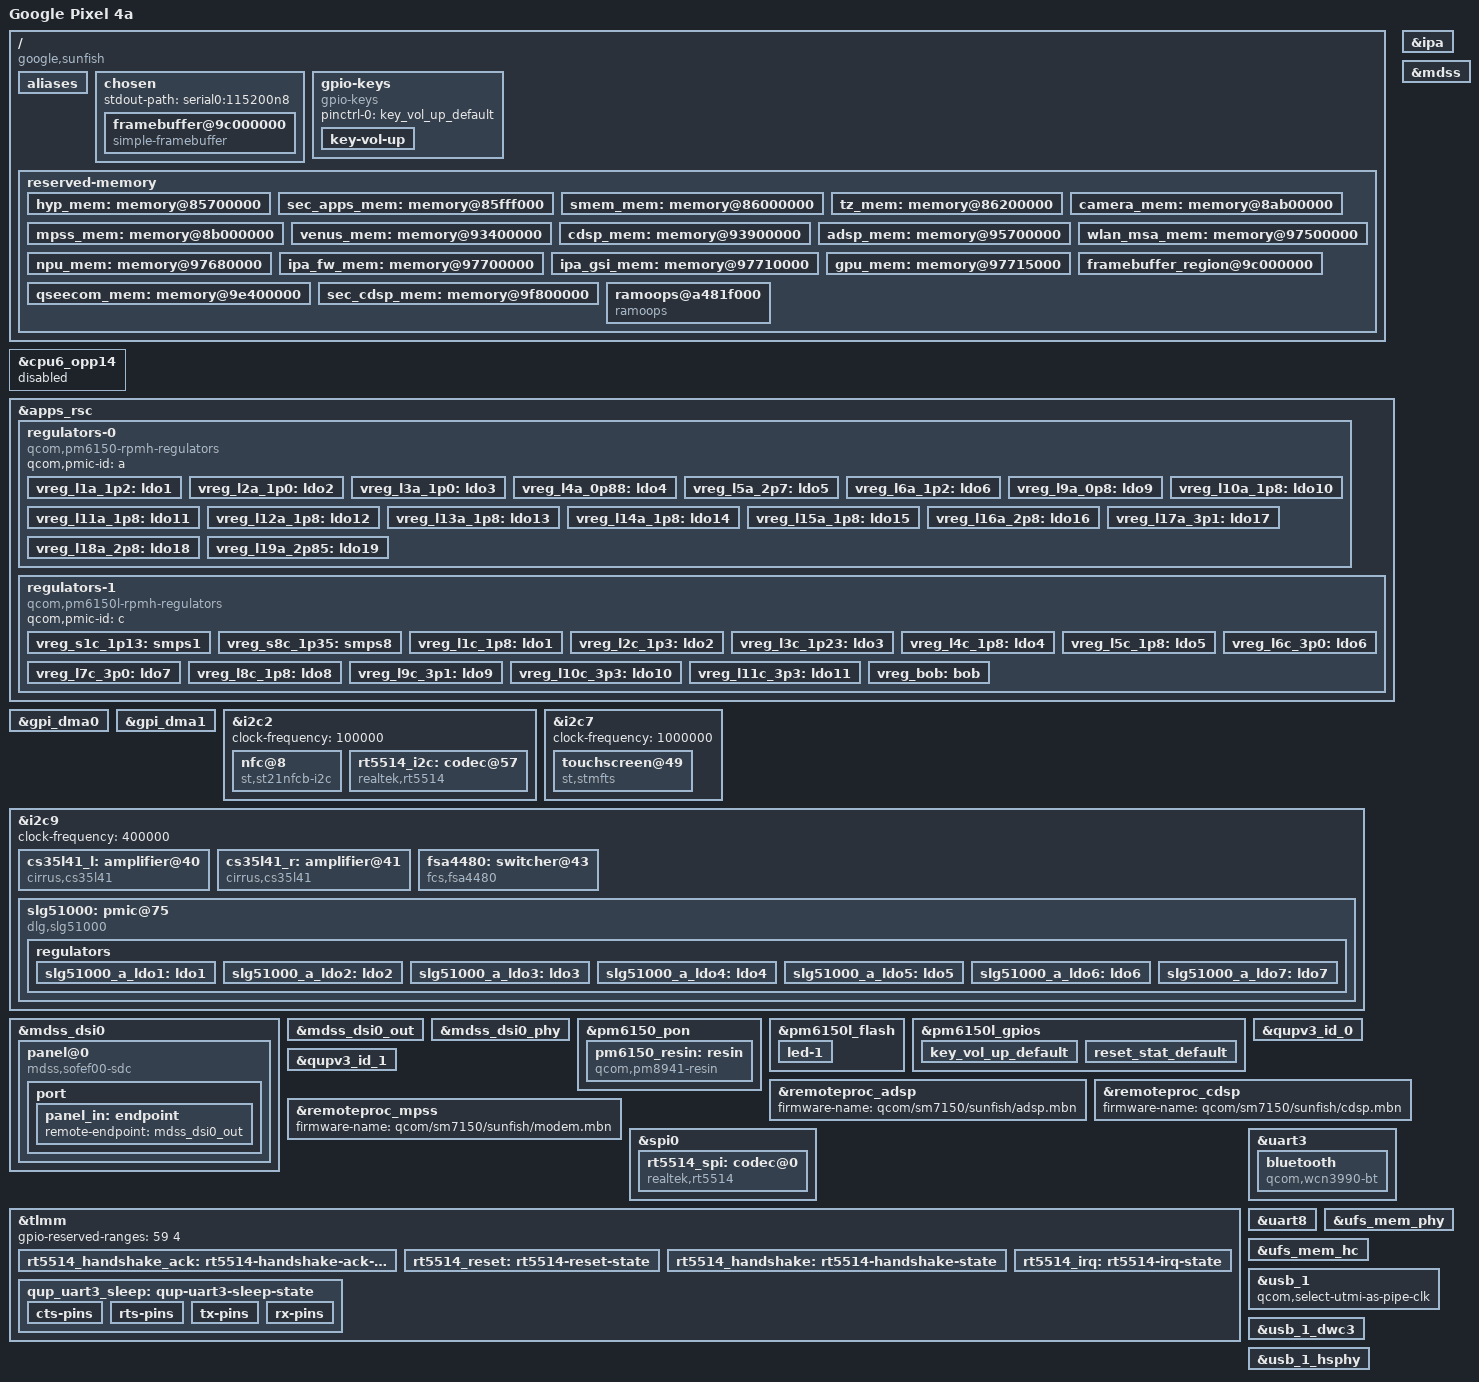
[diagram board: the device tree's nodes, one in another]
// SPDX-License-Identifier: BSD-3-Clause
/*
 * SM7150-AB Google Pixel 4a specific device tree
 *
 * Copyright (c) 2022, Connor Mitchell <c.dog29@hotmail.com>
 * Copyright (c) 2022, Danila Tikhonov <JIaxyga@protonmail.com>
 */

/dts-v1/;

#include <dt-bindings/arm/qcom,ids.h>
#include <dt-bindings/gpio/gpio.h>
#include <dt-bindings/leds/common.h>
#include <dt-bindings/regulator/qcom,rpmh-regulator.h>
#include <dt-bindings/pinctrl/qcom,pmic-gpio.h>

#include "sm7150.dtsi"
#include "pm6150.dtsi"
#include "pm6150l.dtsi"

/*
 * Delete following upstream (sm7150.dtsi) reserved
 * memory mappings which are different in this device.
 */
/delete-node/ &mpss_mem;
/delete-node/ &venus_mem;
/delete-node/ &cdsp_mem;
/delete-node/ &adsp_mem;
/delete-node/ &wlan_msa_mem;
/delete-node/ &npu_mem;
/delete-node/ &ipa_fw_mem;
/delete-node/ &ipa_gsi_mem;
/delete-node/ &gpu_mem;
/delete-node/ &hyp_mem;
/delete-node/ &sec_apps_mem;
/delete-node/ &smem_mem;
/delete-node/ &tz_mem;
/delete-node/ &camera_mem;
/delete-node/ &qseecom_mem;
/delete-node/ &sec_cdsp_mem;

/*
 * Sunfish uses the SM7150-AB SoC.
 * Limit CPU clock to 2.2 GHz
 */

 &cpu6_opp14 {
	status = "disabled";
};

/ {
	model = "Google Pixel 4a";
	compatible = "google,sunfish", "qcom,sm7150";
	chassis-type = "handset";

	qcom,msm-id = <QCOM_ID_SM7150 0>;
	qcom,board-id = <927749 0>;

	aliases {
		bluetooth0 = &bluetooth;
		hsuart0 = &uart3;
		serial0 = &uart8;
		wifi0 = &wifi;
	};

	chosen {
		stdout-path = "serial0:115200n8";
	};

	chosen {
		#address-cells = <2>;
		#size-cells = <2>;
		ranges;

		framebuffer@9c000000 {
			compatible = "simple-framebuffer";
			reg = <0x0 0x9c000000 0x0 (1080 * 2340 * 4)>;
			width = <1080>;
			height = <2340>;
			stride = <(1080 * 4)>;
			format = "a8r8g8b8";
			/*
			 * That's (going to be) a lot of clocks, but it's necessary due
			 * to unused clk cleanup & no panel driver yet (& no dispcc either)..
			 */
			clocks = <&gcc GCC_DISP_SF_AXI_CLK>;
		};
	};

	gpio-keys {
		compatible = "gpio-keys";
		pinctrl-names = "default";
		pinctrl-0 = <&key_vol_up_default>;

		key-vol-up {
			label = "Volume Up";
			linux,code = <KEY_VOLUMEUP>;
			gpios = <&pm6150l_gpios 2 GPIO_ACTIVE_LOW>;
			debounce-interval = <15>;
		};
	};

	reserved-memory { //Sort in order by unit address instead of the name
		hyp_mem: memory@85700000 {
			reg = <0x00 0x85700000 0x00 0x600000>;
			no-map;
		};

		sec_apps_mem: memory@85fff000 {
			reg = <0x00 0x85fff000 0x00 0x1000>;
			no-map;
		};

		smem_mem: memory@86000000 {
			reg = <0x00 0x86000000 0x00 0x200000>;
			no-map;
		};

		tz_mem: memory@86200000 {
			reg = <0x00 0x86200000 0x00 0x2d00000>;
			no-map;
		};

		camera_mem: memory@8ab00000 {
			reg = <0x00 0x8ab00000 0x00 0x500000>;
			no-map;
		};

		mpss_mem: memory@8b000000 {
			reg = <0x0 0x8b000000 0x0 0x9800000>;
			no-map;
		};

		venus_mem: memory@93400000 {
			reg = <0x00 0x94800000 0x00 0x500000>;
			no-map;
		};

		cdsp_mem: memory@93900000 {
			reg = <0x00 0x94d00000 0x00 0x1e00000>;
			no-map;
		};

		adsp_mem: memory@95700000 {
			reg = <0x00 0x96b00000 0x00 0x2200000>;
			no-map;
		};

		wlan_msa_mem: memory@97500000 {
			reg = <0x00 0x98d00000 0x00 0x200000>;
			no-map;
		};

		npu_mem: memory@97680000 {
			reg = <0x00 0x98f00000 0x00 0x80000>;
			no-map;
		};

		ipa_fw_mem: memory@97700000 {
			reg = <0x0 0x98f80000 0x0 0x10000>;
			no-map;
		};

		ipa_gsi_mem: memory@97710000 {
			reg = <0x0 0x98f90000 0x0 0x5000>;
			no-map;
		};

		gpu_mem: memory@97715000 {
			reg = <0x00 0x98f95000 0x00 0x2000>;
			no-map;
		};

		framebuffer_region@9c000000 {
			reg = <0x0 0x9c000000 0x0 (1080 * 2340 * 4)>;
			no-map;
		};

		qseecom_mem: memory@9e400000 {
			reg = <0x00 0x9e400000 0x00 0x1400000>;
			no-map;
		};

		sec_cdsp_mem: memory@9f800000 {
			reg = <0x00 0x9f800000 0x00 0x1e00000>;
			no-map;
		};

		ramoops@a481f000 {
			compatible = "ramoops";
			reg = <0x00 0xa481f000 0x00 0x400000>;

			record-size = <0x40000>;
			pmsg-size = <0x200000>;
			console-size = <0x100000>;
		};
	};
};

&apps_rsc {
	regulators-0 {
		compatible = "qcom,pm6150-rpmh-regulators";
		qcom,pmic-id = "a";

		vreg_l1a_1p2: ldo1 {
			regulator-min-microvolt = <0x10b940>;
			regulator-max-microvolt = <0x13e5c0>;
			regulator-initial-mode = <RPMH_REGULATOR_MODE_HPM>;
		};

		vreg_l2a_1p0: ldo2 {
			regulator-min-microvolt = <0xe6780>;
			regulator-max-microvolt = <0x101d00>;
			regulator-initial-mode = <RPMH_REGULATOR_MODE_HPM>;
		};

		vreg_l3a_1p0: ldo3 {
			regulator-min-microvolt = <0xec540>;
			regulator-max-microvolt = <0x103c40>;
			regulator-initial-mode = <RPMH_REGULATOR_MODE_HPM>;
		};

		vreg_l4a_0p88: ldo4 {
			regulator-min-microvolt = <0xc92c0>;
			regulator-max-microvolt = <0xe09c0>;
			regulator-initial-mode = <RPMH_REGULATOR_MODE_HPM>;
		};

		vreg_l5a_2p7: ldo5 {
			regulator-min-microvolt = <0x27ac40>;
			regulator-max-microvolt = <0x2ab980>;
			regulator-initial-mode = <RPMH_REGULATOR_MODE_HPM>;
		};

		vreg_l6a_1p2: ldo6 {
			regulator-min-microvolt = <0x10b940>;
			regulator-max-microvolt = <0x13e5c0>;
			regulator-initial-mode = <RPMH_REGULATOR_MODE_HPM>;
		};

		vreg_l9a_0p8: ldo9 {
			regulator-min-microvolt = <0x98580>;
			regulator-max-microvolt = <0xb98c0>;
			regulator-initial-mode = <RPMH_REGULATOR_MODE_HPM>;
		};

		vreg_l10a_1p8: ldo10 {
			regulator-min-microvolt = <0x1a3ec0>;
			regulator-max-microvolt = <0x1bf440>;
			regulator-initial-mode = <RPMH_REGULATOR_MODE_HPM>;
		};

		vreg_l11a_1p8: ldo11 {
			regulator-min-microvolt = <0x19e100>;
			regulator-max-microvolt = <0x1e4600>;
			regulator-initial-mode = <RPMH_REGULATOR_MODE_HPM>;
		};

		vreg_l12a_1p8: ldo12 {
			regulator-min-microvolt = <0x19e100>;
			regulator-max-microvolt = <0x1dc900>;
			regulator-initial-mode = <RPMH_REGULATOR_MODE_HPM>;
		};

		vreg_l13a_1p8: ldo13 {
			regulator-min-microvolt = <0x19e100>;
			regulator-max-microvolt = <0x1d0d80>;
			regulator-initial-mode = <RPMH_REGULATOR_MODE_HPM>;
		};

		vreg_l14a_1p8: ldo14 {
			regulator-min-microvolt = <0x1a3ec0>;
			regulator-max-microvolt = <0x1c5200>;
			regulator-initial-mode = <RPMH_REGULATOR_MODE_HPM>;
		};

		vreg_l15a_1p8: ldo15 {
			regulator-min-microvolt = <0x19e100>;
			regulator-max-microvolt = <0x1d0d80>;
			regulator-initial-mode = <RPMH_REGULATOR_MODE_HPM>;
		};

		vreg_l16a_2p8: ldo16 {
			regulator-min-microvolt = <0x24fcc0>;
			regulator-max-microvolt = "\0-i";
			regulator-initial-mode = <RPMH_REGULATOR_MODE_HPM>;
		};

		vreg_l17a_3p1: ldo17 {
			regulator-min-microvolt = <0x2dc6c0>;
			regulator-max-microvolt = "\01Q";
			regulator-initial-mode = <RPMH_REGULATOR_MODE_HPM>;
		};

		vreg_l18a_2p8: ldo18 {
			regulator-min-microvolt = <0x2dc6c0>;
			regulator-max-microvolt = <0x2dc6c0>;
			regulator-initial-mode = <RPMH_REGULATOR_MODE_HPM>;
		};

		vreg_l19a_2p85: ldo19 {
			regulator-min-microvolt = <0x2cec00>;
			regulator-max-microvolt = <0x326a40>;
			regulator-initial-mode = <RPMH_REGULATOR_MODE_HPM>;
		};
	};

	regulators-1 {
		compatible = "qcom,pm6150l-rpmh-regulators";
		qcom,pmic-id = "c";

		vreg_s1c_1p13: smps1 {
			regulator-min-microvolt = <0xf4240>;
			regulator-max-microvolt = <0x124f80>;
		};

		vreg_s8c_1p35: smps8 {
			regulator-min-microvolt = <0x124f80>;
			regulator-max-microvolt = <0x1a65d0>;
		};

		vreg_l1c_1p8: ldo1 {
			regulator-min-microvolt = <0x18a880>;
			regulator-max-microvolt = <0x1e4600>;
			regulator-initial-mode = <RPMH_REGULATOR_MODE_HPM>;
		};

		vreg_l2c_1p3: ldo2 {
			regulator-min-microvolt = <0x124f80>;
			regulator-max-microvolt = <0x14a140>;
			regulator-initial-mode = <RPMH_REGULATOR_MODE_HPM>;
		};

		vreg_l3c_1p23: ldo3 {
			regulator-min-microvolt = <0x1174c0>;
			regulator-max-microvolt = <0x132a40>;
			regulator-initial-mode = <RPMH_REGULATOR_MODE_HPM>;
		};

		vreg_l4c_1p8: ldo4 {
			regulator-min-microvolt = <0x192580>;
			regulator-max-microvolt = <0x2d0370>;
			regulator-initial-mode = <RPMH_REGULATOR_MODE_HPM>;
		};

		vreg_l5c_1p8: ldo5 {
			regulator-min-microvolt = <0x192580>;
			regulator-max-microvolt = <0x2d0370>;
			regulator-initial-mode = <RPMH_REGULATOR_MODE_HPM>;
		};

		vreg_l6c_3p0: ldo6 {
			regulator-min-microvolt = <0x2d2a80>;
			regulator-max-microvolt = <0x326a40>;
			regulator-initial-mode = <RPMH_REGULATOR_MODE_HPM>;
			regulator-allow-set-load;
			regulator-allowed-modes = <RPMH_REGULATOR_MODE_LPM
						   RPMH_REGULATOR_MODE_HPM>;
		};

		vreg_l7c_3p0: ldo7 {
			regulator-min-microvolt = <0x2dc6c0>;
			regulator-max-microvolt = <0x328980>;
			regulator-initial-mode = <RPMH_REGULATOR_MODE_HPM>;
		};

		vreg_l8c_1p8: ldo8 {
			regulator-min-microvolt = <0x1b7740>;
			regulator-max-microvolt = <0x1cfde0>;
			regulator-initial-mode = <RPMH_REGULATOR_MODE_HPM>;
		};

		/*
		 * Downstream specifies a range of 2950-3312mV.
		 * Tighten the range to 2950-3100mV.
		 */
		vreg_l9c_3p1: ldo9 {
			regulator-min-microvolt = <0x2d0370>;
			regulator-max-microvolt = <0x328980>;
			regulator-initial-mode = <RPMH_REGULATOR_MODE_HPM>;
			regulator-allow-set-load;
			regulator-allowed-modes = <RPMH_REGULATOR_MODE_LPM
						   RPMH_REGULATOR_MODE_HPM>;
		};

		vreg_l10c_3p3: ldo10 {
			regulator-min-microvolt = <0x30d400>;
			regulator-max-microvolt = <0x328980>;
			regulator-initial-mode = <RPMH_REGULATOR_MODE_HPM>;
		};

		vreg_l11c_3p3: ldo11 {
			regulator-min-microvolt = <0x2d0370>;
			regulator-max-microvolt = <0x33e140>;
			regulator-initial-mode = <RPMH_REGULATOR_MODE_HPM>;
		};

		vreg_bob: bob {
			regulator-min-microvolt = "\02K";
			regulator-max-microvolt = <0x3c6cc0>;
			regulator-initial-mode = <RPMH_REGULATOR_MODE_AUTO>;
			regulator-allow-bypass;
		};
	};
};

&gpi_dma0 {
	status = "okay";
};

&gpi_dma1 {
	status = "okay";
};

&i2c2 {
	clock-frequency = <100000>;
	status = "okay";
	nfc@8 {
		compatible = "st,st21nfcb-i2c";
		reg = <0x08>;

		interrupt-parent = <&tlmm>;
		interrupts = <37 IRQ_TYPE_NONE>;
		irq-gpio = <&tlmm 37 GPIO_ACTIVE_HIGH>;

		clkreq-gpios = <&tlmm 31 GPIO_ACTIVE_HIGH>;
		reset-gpios = <&tlmm 67 GPIO_ACTIVE_HIGH>;
		pidle-gpios = <&tlmm 94 GPIO_ACTIVE_HIGH>;

		ese-present;
		uicc-present;
	};

	/* nqx,nq-nci (nfc) @ 28 */

	rt5514_i2c: codec@57 {
		compatible = "realtek,rt5514";
		reg = <0x57>;
		reset-gpio = <&tlmm 33 GPIO_ACTIVE_HIGH>;
		pinctrl-names = "default";
		pinctrl-0 = <&rt5514_reset>;
	};
};

&i2c7 {
	clock-frequency = <1000000>;
	status = "okay";
	touchscreen@49 {
		compatible = "st,stmfts";
		reg = <0x49>;
		interrupt-parent = <&tlmm>;
		interrupts = <1 IRQ_TYPE_LEVEL_LOW>;
		touchscreen-size-x = <1079>;
		touchscreen-size-y = <2339>;
		avdd-supply = <&vreg_l13a_1p8>;
		vdd-supply = <&vreg_l14a_1p8>;
	};
};

&i2c9 {
	clock-frequency = <400000>;
	status= "okay";
	/* microchip,pac193x (dc power monitor) @ 10 */

	cs35l41_l: amplifier@40 {
		compatible = "cirrus,cs35l41";
		reg = <0x40>;
		interrupt-parent = <&tlmm>;
		interrupts = <64 IRQ_TYPE_LEVEL_HIGH>;
		reset-gpios = <&tlmm 8 GPIO_ACTIVE_HIGH>;
		cirrus,boost-peak-milliamp = <3700>;
		cirrus,boost-ind-nanohenry = <1000>;
		cirrus,boost-cap-microfarad = <15>;
		cirrus,asp-sdout-hiz = <3>;
		cirrus,gpio2-src-select = <5>;
		cirrus,gpio2-output-enable;
		#sound-dai-cells = <1>;
	};

	cs35l41_r: amplifier@41 {
		compatible = "cirrus,cs35l41";
		reg = <0x41>;
		interrupt-parent = <&tlmm>;
		interrupts = <65 IRQ_TYPE_LEVEL_HIGH>;
		reset-gpios = <&tlmm 11 GPIO_ACTIVE_HIGH>;
		cirrus,boost-peak-milliamp = <3700>;
		cirrus,boost-ind-nanohenry = <1000>;
		cirrus,boost-cap-microfarad = <15>;
		cirrus,asp-sdout-hiz = <3>;
		cirrus,gpio2-src-select = <5>;
		cirrus,gpio2-output-enable;
		#sound-dai-cells = <1>;
	};

	fsa4480: switcher@43 {
		compatible = "fcs,fsa4480";
		reg = <0x43>;

		interrupts-extended = <&tlmm 42 IRQ_TYPE_LEVEL_LOW>;

		vcc-supply = <&vreg_bob>;

		mode-switch;
		orientation-switch;
	};

	/* st,m24c08 (e2prom) @ 50 */
	/* ti,drv2624 (haptic) @ 5a */

	slg51000: pmic@75 {
		compatible = "dlg,slg51000";
		reg = <0x75>;
		dlg,cs-gpios = <&tlmm 4 GPIO_ACTIVE_HIGH>,
			       <&tlmm 6 GPIO_ACTIVE_HIGH>;
		dlg,enable-gpios = <&tlmm 1 GPIO_ACTIVE_HIGH>,
				   <&tlmm 5 GPIO_ACTIVE_HIGH>;

		regulators {
			slg51000_a_ldo1: ldo1 {
				regulator-name = "slg51000_a_ldo1";
				regulator-min-microvolt = <0x225510>;
				regulator-max-microvolt = <0x325aa0>;
			};

			slg51000_a_ldo2: ldo2 {
				regulator-name = "slg51000_a_ldo2";
				regulator-min-microvolt = <0x225510>;
				regulator-max-microvolt = <0x325aa0>;
			};

			slg51000_a_ldo3: ldo3 {
				regulator-name = "slg51000_a_ldo3";
				regulator-min-microvolt = <0x124f80>;
				regulator-max-microvolt = <0x393870>;
			};

			slg51000_a_ldo4: ldo4 {
				regulator-name = "slg51000_a_ldo4";
				regulator-min-microvolt = <0x124f80>;
				regulator-max-microvolt = <0x393870>;
			};

			slg51000_a_ldo5: ldo5 {
				regulator-name = "slg51000_a_ldo5";
				regulator-min-microvolt = <0x7a120>;
				regulator-max-microvolt = <0x124f80>;
			};

			slg51000_a_ldo6: ldo6 {
				regulator-name = "slg51000_a_ldo6";
				regulator-min-microvolt = <0x7a120>;
				regulator-max-microvolt = <0x124f80>;
			};

			slg51000_a_ldo7: ldo7 {
				regulator-name = "slg51000_a_ldo7";
				regulator-min-microvolt = <0x124f80>;
				regulator-max-microvolt = <0x393870>;
			};
		};
	};
};

&ipa {
	memory-region = <&ipa_fw_mem>;
	firmware-name = "qcom/sm7150/sunfish/ipa_fws.mbn";
	status = "okay";
};

&mdss {
	status = "okay";
};

&mdss_dsi0 {
	panel@0 {
		compatible = "mdss,sofef00-sdc";
		reg = <0>;

		reset-gpios = <&pm6150l_gpios 9 GPIO_ACTIVE_LOW>;

		port {
			panel_in: endpoint {
				remote-endpoint = <&mdss_dsi0_out>;
			};
		};
	};
};

&mdss_dsi0_out {
	data-lanes = <0 1 2 3>;
	remote-endpoint = <&panel_in>;
	status = "okay";
};
	
&mdss_dsi0_phy {
	status = "okay";
};

&pm6150_pon {
	pm6150_resin: resin {
		compatible = "qcom,pm8941-resin";
		interrupts = <0x0 0x8 1 IRQ_TYPE_EDGE_BOTH>;
		debounce = <15625>;
		bias-pull-up;
		linux,code = <KEY_VOLUMEDOWN>;
	};
};

&pm6150l_flash {
	status = "okay";

	led-1 {
		function = LED_FUNCTION_FLASH;
		color = <LED_COLOR_ID_WHITE>;
		led-sources = <1>;
		led-max-microamp = <150000>;
		flash-max-microamp = <1000000>;
		flash-max-timeout-us = <1280000>;
	};
};

&pm6150l_gpios {
	key_vol_up_default: key_vol_up_default {
		pins = "gpio2";
		function = "normal";
		input-enable;
		bias-pull-up;
		power-source = <0>;
	};

	reset_stat_default: reset_stat_default {
		pins = "gpio8";
		function = "normal";
		power-source = <1>;
		output-low;
		input-disable;
	};
};

&qupv3_id_0 {
	status = "okay";
};

&qupv3_id_1 {
	status = "okay";
};

&remoteproc_adsp {
	firmware-name = "qcom/sm7150/sunfish/adsp.mbn";
	status = "okay";
};

&remoteproc_cdsp {
	firmware-name = "qcom/sm7150/sunfish/cdsp.mbn";
	status = "okay";
};

&remoteproc_mpss {
	firmware-name = "qcom/sm7150/sunfish/modem.mbn";
	status = "okay";
};

&spi0 {
	status = "okay";

	rt5514_spi: codec@0 {
		compatible = "realtek,rt5514";
		reg = <0>;

		spi-max-frequency = <10000000>;

		interrupt-parent = <&tlmm>;
		interrupts = <58 IRQ_TYPE_NONE>,
			     <30 IRQ_TYPE_NONE>;
		interrupt-names = "irq", "handshake-ack";
		irq-gpio = <&tlmm 58 GPIO_ACTIVE_HIGH>;

		handshake-gpio = <&tlmm 57 0>;
		handshake-ack-gpio = <&tlmm 30 0>;
		pinctrl-names = "default";
		pinctrl-0 = <&rt5514_irq>,
			    <&rt5514_handshake>,
			    <&rt5514_handshake_ack>;
	};
};

&spi0 {
	status = "okay";

	/* google,citadel @ 0 */
	/* st,st54j_se @ 1 */
};

&tlmm {
	gpio-reserved-ranges = <59 4>;

	rt5514_handshake_ack: rt5514-handshake-ack-state {
		pins = "gpio30";
		function = "gpio";
		drive-strength = <2>;
		bias-pull-down;
		input-enable;
	};

	rt5514_reset: rt5514-reset-state {
		pins = "gpio33";
		function = "gpio";
		drive-strength = <2>;
		output-high;
	};

	rt5514_handshake: rt5514-handshake-state {
		pins = "gpio57";
		function = "gpio";
		drive-strength = <2>;
		output-low;
	};

	rt5514_irq: rt5514-irq-state {
		pins = "gpio58";
		function = "gpio";
		drive-strength = <2>;
		bias-pull-down;
		input-enable;
	};

	qup_uart3_sleep: qup-uart3-sleep-state {
		cts-pins {
			pins = "gpio38";
			function = "gpio";
			bias-pull-down;
		};

		rts-pins {
			pins = "gpio39";
			function = "gpio";
			bias-pull-down;
		};

		tx-pins {
			pins = "gpio40";
			function = "gpio";
			bias-pull-up;
		};

		rx-pins {
			pins = "gpio41";
			function = "gpio";
			bias-pull-up;
		};
	};
};

&uart3 {
	status = "okay";

	/delete-property/interrupts;
	interrupts-extended = <&intc GIC_SPI 604 IRQ_TYPE_LEVEL_HIGH>,
			      <&tlmm 41 IRQ_TYPE_EDGE_FALLING>;

	pinctrl-names = "default", "sleep";
	pinctrl-1 = <&qup_uart3_sleep>;

	bluetooth: bluetooth {
		compatible = "qcom,wcn3990-bt";

		vddio-supply = <&vreg_l10a_1p8>;
		vddxo-supply = <&vreg_l1c_1p8>;
		vddrf-supply = <&vreg_l2c_1p3>;
		vddch0-supply = <&vreg_l10c_3p3>;
		max-speed = <3200000>;
	};
};

&uart8 {
	status = "okay";
};

&ufs_mem_phy {
	status = "okay";

	vdda-phy-supply = <&vreg_l4a_0p88>;
	vdda-pll-supply = <&vreg_l3c_1p23>;
};

&ufs_mem_hc {
	status = "okay";

	vcc-supply = <&vreg_l19a_2p85>;
	vcc-max-microamp = <600000>;
	vccq2-supply = <&vreg_l12a_1p8>;
	vccq2-max-microamp = <600000>;
};

&usb_1 {
	status = "okay";

	qcom,select-utmi-as-pipe-clk;
};

&usb_1_dwc3 {
	status = "okay";

	maximum-speed = "high-speed";
	dr_mode = "peripheral";
};

&usb_1_hsphy {
	status = "okay";
	vdd-supply = <&vreg_l4a_0p88>;
	vdda-pll-supply = <&vreg_l11a_1p8>;
	vdda-phy-dpdm-supply = <&vreg_l17a_3p1>;
};
